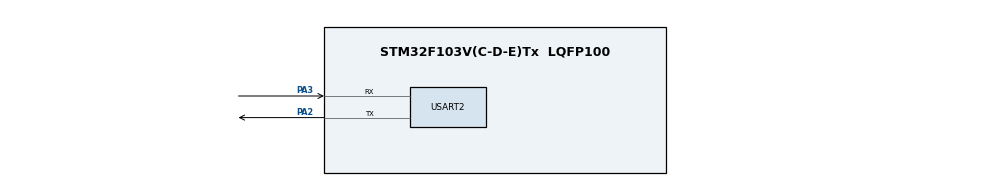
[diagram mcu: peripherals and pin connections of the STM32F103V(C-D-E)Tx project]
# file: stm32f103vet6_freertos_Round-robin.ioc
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FREERTOS.Tasks01=defaultTask,24,128,StartDefaultTask,Default,NULL,Dynamic,NULL,NULL;TaskB,24,128,StartTaskB,Default,NULL,Dynamic,NULL,NULL;TaskA,24,128,StartTaskA,Default,NULL,Dynamic,NULL,NULL
Mcu.Family=STM32F1
Mcu.Name=STM32F103V(C-D-E)Tx
Mcu.Package=LQFP100
NVIC.PriorityGroup=NVIC_PRIORITYGROUP_4
OSC_IN.Mode=HSE-External-Oscillator
OSC_IN.Signal=RCC_OSC_IN
OSC_OUT.Mode=HSE-External-Oscillator
OSC_OUT.Signal=RCC_OSC_OUT
PA13.Mode=Trace_Asynchronous_SW
PA13.Signal=SYS_JTMS-SWDIO
PA14.Mode=Trace_Asynchronous_SW
PA14.Signal=SYS_JTCK-SWCLK
PA2.Mode=Asynchronous
PA2.Signal=USART2_TX
PA3.Mode=Asynchronous
PA3.Signal=USART2_RX
PB3.Mode=Trace_Asynchronous_SW
PB3.Signal=SYS_JTDO-TRACESWO
ProjectManager.HeapSize=0x200
ProjectManager.StackSize=0x400
ProjectManager.TargetToolchain=STM32CubeIDE
RCC.APB1Freq_Value=8000000
RCC.APB2Freq_Value=8000000
USART2.VirtualMode=VM_ASYNC
VP_FREERTOS_VS_CMSIS_V2.Mode=CMSIS_V2
board=custom

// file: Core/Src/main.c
/* USER CODE BEGIN Header */
/**
  ******************************************************************************
  * @file           : main.c
  * @brief          : Main program body
  ******************************************************************************
  * @attention
  *
  * Copyright (c) 2026 STMicroelectronics.
  * All rights reserved.
  *
  * This software is licensed under terms that can be found in the LICENSE file
  * in the root directory of this software component.
  * If no LICENSE file comes with this software, it is provided AS-IS.
  *
  ******************************************************************************
  */
/* USER CODE END Header */
#include "main.h"
#include "cmsis_os.h"

/* USER CODE BEGIN Includes */
#include "stdio.h"
#include "string.h"
#include "freertos.h"
/* USER CODE END Includes */

UART_HandleTypeDef huart2;

/* Definitions for defaultTask */
osThreadId_t defaultTaskHandle;
const osThreadAttr_t defaultTask_attributes = {
  .name = "defaultTask",
  .stack_size = 128 * 4,
  .priority = (osPriority_t) osPriorityNormal,
};
/* Definitions for TaskB */
osThreadId_t TaskBHandle;
const osThreadAttr_t TaskB_attributes = {
  .name = "TaskB",
  .stack_size = 128 * 4,
  .priority = (osPriority_t) osPriorityNormal,
};
/* Definitions for TaskA */
osThreadId_t TaskAHandle;
const osThreadAttr_t TaskA_attributes = {
  .name = "TaskA",
  .stack_size = 128 * 4,
  .priority = (osPriority_t) osPriorityNormal,
};
/* USER CODE BEGIN PV */
volatile uint32_t countA = 0;
volatile uint32_t countB = 0;
/* USER CODE END PV */

void SystemClock_Config(void);
static void MX_GPIO_Init(void);
static void MX_USART2_UART_Init(void);
void StartDefaultTask(void *argument);
void StartTaskB(void *argument);
void StartTaskA(void *argument);

/* USER CODE BEGIN 0 */
int _write(int file, char *ptr, int len)
{
	for(int i=0;i<len;i++)
		ITM_SendChar((*ptr++));
	return len;
}

void uart_print(char *msg)
{
	HAL_UART_Transmit(&huart2, (uint8_t*)msg, strlen(msg), HAL_MAX_DELAY);
}
/* USER CODE END 0 */

int main(void)
{

  /* MCU Configuration--------------------------------------------------------*/

  /* Reset of all peripherals, Initializes the Flash interface and the Systick. */
  HAL_Init();

  /* Configure the system clock */
  SystemClock_Config();

  /* Initialize all configured peripherals */
  MX_GPIO_Init();
  MX_USART2_UART_Init();

  /* Init scheduler */
  osKernelInitialize();

  /* Create the thread(s) */
  /* creation of defaultTask */
  defaultTaskHandle = osThreadNew(StartDefaultTask, NULL, &defaultTask_attributes);

  /* creation of TaskB */
  TaskBHandle = osThreadNew(StartTaskB, NULL, &TaskB_attributes);

  /* creation of TaskA */
  TaskAHandle = osThreadNew(StartTaskA, NULL, &TaskA_attributes);

  /* Start scheduler */
  osKernelStart();

  /* We should never get here as control is now taken by the scheduler */

  /* Infinite loop */
  while (1)
  {

  }
}

void SystemClock_Config(void)
{
  RCC_OscInitTypeDef RCC_OscInitStruct = {0};
  RCC_ClkInitTypeDef RCC_ClkInitStruct = {0};

  /** Initializes the RCC Oscillators according to the specified parameters
  * in the RCC_OscInitTypeDef structure.
  */
  RCC_OscInitStruct.OscillatorType = RCC_OSCILLATORTYPE_HSI;
  RCC_OscInitStruct.HSIState = RCC_HSI_ON;
  RCC_OscInitStruct.HSICalibrationValue = RCC_HSICALIBRATION_DEFAULT;
  RCC_OscInitStruct.PLL.PLLState = RCC_PLL_NONE;
  if (HAL_RCC_OscConfig(&RCC_OscInitStruct) != HAL_OK)
  {
    Error_Handler();
  }

  /** Initializes the CPU, AHB and APB buses clocks
  */
  RCC_ClkInitStruct.ClockType = RCC_CLOCKTYPE_HCLK|RCC_CLOCKTYPE_SYSCLK
                              |RCC_CLOCKTYPE_PCLK1|RCC_CLOCKTYPE_PCLK2;
  RCC_ClkInitStruct.SYSCLKSource = RCC_SYSCLKSOURCE_HSI;
  RCC_ClkInitStruct.AHBCLKDivider = RCC_SYSCLK_DIV1;
  RCC_ClkInitStruct.APB1CLKDivider = RCC_HCLK_DIV1;
  RCC_ClkInitStruct.APB2CLKDivider = RCC_HCLK_DIV1;

  if (HAL_RCC_ClockConfig(&RCC_ClkInitStruct, FLASH_LATENCY_0) != HAL_OK)
  {
    Error_Handler();
  }
}

static void MX_USART2_UART_Init(void)
{

  huart2.Instance = USART2;
  huart2.Init.BaudRate = 115200;
  huart2.Init.WordLength = UART_WORDLENGTH_8B;
  huart2.Init.StopBits = UART_STOPBITS_1;
  huart2.Init.Parity = UART_PARITY_NONE;
  huart2.Init.Mode = UART_MODE_TX_RX;
  huart2.Init.HwFlowCtl = UART_HWCONTROL_NONE;
  huart2.Init.OverSampling = UART_OVERSAMPLING_16;
  if (HAL_UART_Init(&huart2) != HAL_OK)
  {
    Error_Handler();
  }

}

static void MX_GPIO_Init(void)
{

  /* GPIO Ports Clock Enable */
  __HAL_RCC_GPIOA_CLK_ENABLE();
  __HAL_RCC_GPIOB_CLK_ENABLE();

}

void StartDefaultTask(void *argument)
{
  /* USER CODE BEGIN 5 */
  /* Infinite loop */

  for(;;)
  {
	  osDelay(1000);
  }
  /* USER CODE END 5 */
}

void StartTaskB(void *argument)
{
  /* USER CODE BEGIN StartTaskB */
  /* Infinite loop */
  for(;;)
  {
	  printf("dang xu ly du lieu\r\n");
//	  osDelay(1000);
  }
  /* USER CODE END StartTaskB */
}

void StartTaskA(void *argument)
{
  /* USER CODE BEGIN StartTaskA */
  /* Infinite loop */
	  for(;;)
  {
		  printf("dang thu thap du lieu\r\n");
		  osThreadSetPriority(TaskAHandle, osPriorityHigh);
//		  osDelay(1000);
  }
  /* USER CODE END StartTaskA */
}

void Error_Handler(void)
{
  __disable_irq();
  while (1)
  {
  }
}
